# MIMXRT1021 register map
Vendor: nxp.com; File version: 1.0
CPU: CM7 r0p1, little endian, MPU, FPU, VTOR, 4 interrupt priority bits
Registers are 32-bit, read-write, reset 0x0 unless marked. A register's access mark holds for its fields unless they carry their own. Offsets are from the block's base; [hi:lo] are bit positions; {n}, {i} and the like mark numbered series.

## CMP1 — High-Speed Comparator (CMP), Voltage Reference (VREF) Digital-to-Analog Converter (DAC), and Analog Mux (ANMUX)
Base 0x40094000; register names take the prefix CMP1_
Same registers: CMP2 0x40094008 (register names take the prefix CMP2_), CMP3 0x40094010 (register names take the prefix CMP3_), CMP4 0x40094018 (register names take the prefix CMP4_)
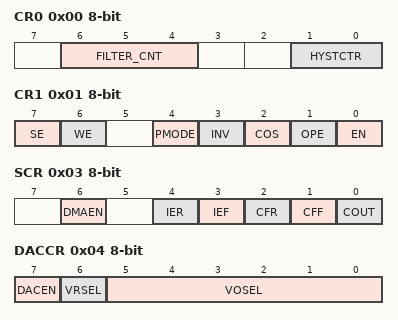
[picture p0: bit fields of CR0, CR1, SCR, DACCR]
0x00 CR0 8-bit — CMP Control Register 0
  [6:4] FILTER_CNT — Filter Sample Count
    0=Filter is disabled. If SE = 1, then COUT is a logic 0. This is not a legal state, and is not recommended. If SE = 0, COUT = COUTA.; 1=One sample must agree. The comparator output is simply sampled.; {v}={v} consecutive samples must agree (v=2..7)
  [1:0] HYSTCTR — Comparator hard block hysteresis control
    {v}=Level {v} (v=0..3)
0x01 CR1 8-bit — CMP Control Register 1
  [7] SE — Sample Enable
    0=Sampling mode is not selected; 1=Sampling mode is selected
  [6] WE — Windowing Enable
    0=Windowing mode is not selected; 1=Windowing mode is selected
  [4] PMODE — Power Mode Select
    0=Low-Speed (LS) Comparison mode selected. In this mode, CMP has slower output propagation delay and lower current consumption.; 1=High-Speed (HS) Comparison mode selected. In this mode, CMP has faster output propagation delay and higher current consumption.
  [3] INV — Comparator INVERT
    0=Does not invert the comparator output; 1=Inverts the comparator output
  [2] COS — Comparator Output Select
    0=Set the filtered comparator output (CMPO) to equal COUT; 1=Set the unfiltered comparator output (CMPO) to equal COUTA
  [1] OPE — Comparator Output Pin Enable
    0=CMPO is not available on the associated CMPO output pin. If the comparator does not own the pin, this field has no effect.; 1=CMPO is available on the associated CMPO output pin. The comparator output (CMPO) is driven out on the associated CMPO output pin if the comparator owns the pin. If the comparator does not own the field, this bit has no effect.
  [0] EN — Comparator Module Enable
    0=Analog Comparator is disabled; 1=Analog Comparator is enabled
0x02 FPR 8-bit — CMP Filter Period Register
  [7:0] FILT_PER — Filter Sample Period
0x03 SCR 8-bit — CMP Status and Control Register
  [6] DMAEN — DMA Enable Control
    0=DMA is disabled; 1=DMA is enabled
  [4] IER — Comparator Interrupt Enable Rising
    0=Interrupt is disabled; 1=Interrupt is enabled
  [3] IEF — Comparator Interrupt Enable Falling
    0=Interrupt is disabled; 1=Interrupt is enabled
  [2] CFR write-1-clears — Analog Comparator Flag Rising
    0=Rising-edge on COUT has not been detected; 1=Rising-edge on COUT has occurred
  [1] CFF write-1-clears — Analog Comparator Flag Falling
    0=Falling-edge on COUT has not been detected; 1=Falling-edge on COUT has occurred
  [0] COUT ro — Analog Comparator Output
0x04 DACCR 8-bit — DAC Control Register
  [7] DACEN — DAC Enable
    0=DAC is disabled; 1=DAC is enabled
  [6] VRSEL — Supply Voltage Reference Source Select
    0=Vin1 is selected as resistor ladder network supply reference; 1=Vin2 is selected as resistor ladder network supply reference
  [5:0] VOSEL — DAC Output Voltage Select
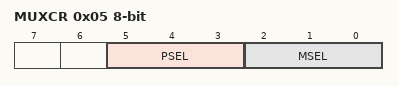
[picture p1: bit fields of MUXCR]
0x05 MUXCR 8-bit — MUX Control Register
  [5:3] PSEL — Plus Input Mux Control
    {v}=IN{v} (v=0..7)
  [2:0] MSEL — Minus Input Mux Control
    {v}=IN{v} (v=0..7)

## IOMUXC_SNVS_GPR — IOMUXC
Base 0x400A4000; register names take the prefix IOMUXC_SNVS_GPR_
{0x0+4i} GPR{i} ro (i=0..2) — GPR{i} General Purpose Register
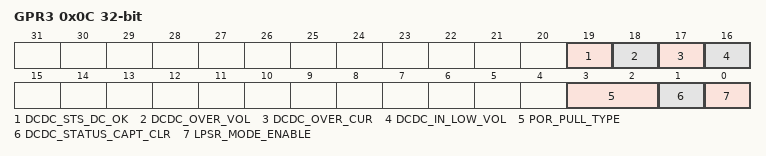
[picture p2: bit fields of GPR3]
0x0C GPR3 — GPR3 General Purpose Register
  [19] DCDC_STS_DC_OK ro — DCDC status OK
    0=DCDC is ramping up and not ready; 1=DCDC is ready
  [18] DCDC_OVER_VOL ro — DCDC output over voltage alert
    0=No over voltage detected; 1=Over voltage detected
  [17] DCDC_OVER_CUR ro — DCDC output over current alert
    0=No over current detected; 1=Over current detected
  [16] DCDC_IN_LOW_VOL ro — DCDC_IN low voltage detect.
    0=DCDC_IN is ok; 1=DCDC_IN is too low
  [3:2] POR_PULL_TYPE — POR_B pad control
    0=100 Ohm pull up enabled for POR_B always; 1=Disable pull in SNVS mode, 100 Ohm pull up enabled otherwise; 2=Disable pull of POR_B always; 3=100 Ohm pull down enabled in SNVS mode, 100 Ohm pull up enabled otherwise
  [1] DCDC_STATUS_CAPT_CLR — DCDC captured status clear
  [0] LPSR_MODE_ENABLE — Set to enable LPSR mode.
    0=SNVS domain will reset when system reset happens; 1=SNVS domain will only reset with SNVS POR

## Notices in the file
Copyright 2016-2022 NXP
All rights reserved.
SPDX-License-Identifier: BSD-3-Clause
